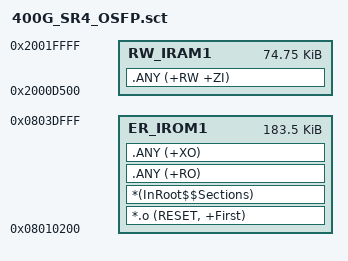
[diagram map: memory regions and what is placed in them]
; *************************************************************
; *** Scatter-Loading Description File generated by uVision ***
; *************************************************************

LR_IROM1 0x08010200 0x0002DE00  {    ; load region size_region
  ER_IROM1 0x08010200 0x0002DE00  {  ; load address = execution address
   *.o (RESET, +First)
   *(InRoot$$Sections)
   .ANY (+RO)
   .ANY (+XO)
  }
  RW_IRAM1 0x2000D500 0x00012B00  {  ; RW data
   .ANY (+RW +ZI)
  }
}

